# STM32WBA52xx register map
File version: 1.0
Registers are 32-bit, read-write, reset 0x0 unless marked. A register's access mark holds for its fields unless they carry their own. Offsets are from the block's base; [hi:lo] are bit positions; {n}, {i} and the like mark numbered series; 'fields as' and 'values as' point back to an identical list.

## GPDMA1 — DMA Controller
Base 0x40020000
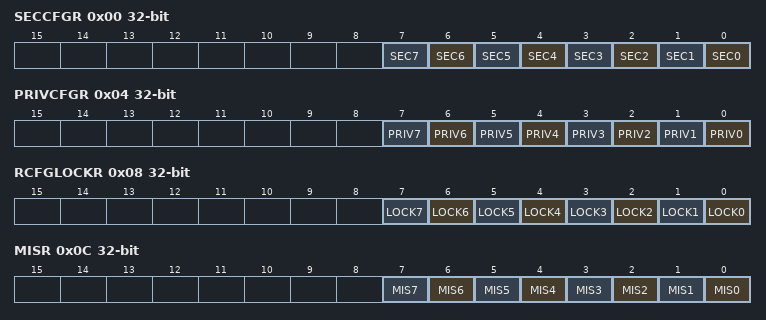
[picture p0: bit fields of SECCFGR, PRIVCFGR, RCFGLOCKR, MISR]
0x00 SECCFGR — DMA secure configuration register
  [n] SEC{n} (n=0..7) — Secure State of Channel {n}
0x04 PRIVCFGR — DMA privileged configuration register
  [n] PRIV{n} (n=0..7) — Privileged State of Channel {n}
0x08 RCFGLOCKR — DMA secure and privilege lock register
  [n] LOCK{n} (n=0..7) — Privileged and Secure State Lock of Channel {n}
0x0C MISR — DMA non secure masked interrupt status register
  [n] MIS{n} (n=0..7) — Masked Interrupt State of Non-Secure Channel {n}
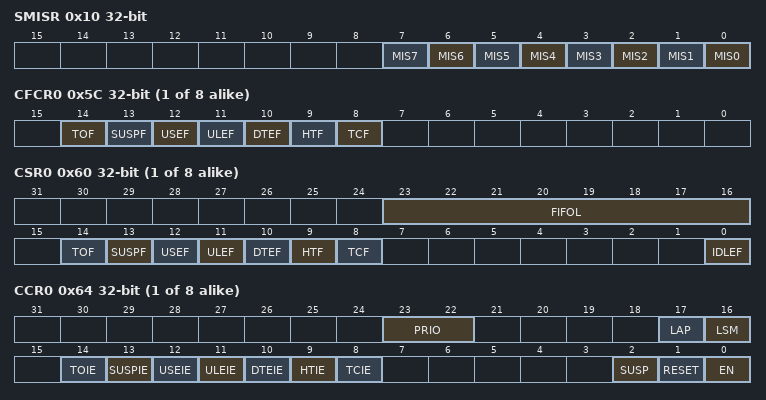
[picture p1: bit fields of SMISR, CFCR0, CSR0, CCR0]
0x10 SMISR — DMA secure masked interrupt status register
  [n] MIS{n} (n=0..7) — Masked Interrupt State of Secure Channel {n}
{0x50+0x80*i} CLBAR{i} (i=0..7) — DMA channel x linked-list base address register
  [31:16] LBA — Linked-list Base Address of DMA channel x
{0x5C+0x80*i} CFCR{i} (i=0..7) — DMA channel x flag clear register
  [14] TOF — Trigger overrun flag clear
  [13] SUSPF — Completed suspension flag clear
  [12] USEF — User setting error flag clear
  [11] ULEF — Update linked-list item error flag clear
  [10] DTEF — Data transfer error flag clear
  [9] HTF — Half transfer complete flag clear
  [8] TCF — Transfer complete flag clear
{0x60+0x80*i} CSR{i} (i=0..7) — DMA channel x flag status register
  [23:16] FIFOL — Monitored FIFO level in bytes
  [14] TOF — Trigger overrun event flag
  [13] SUSPF — User setting error flag
  [12] USEF — User setting error flag
  [11] ULEF — Update linked-list item error flag
  [10] DTEF — Data transfer error flag
  [9] HTF — Half transfer complete flag
  [8] TCF — Transfer complete flag
  [0] IDLEF — Idle flag
{0x64+0x80*i} CCR{i} (i=0..7) — DMA channel x control register
  [23:22] PRIO — Priority level
  [17] LAP — Linked-list allocated port
  [16] LSM — Link step mode
  [14] TOIE — Trigger overrun interrupt enable
  [13] SUSPIE — Completed suspension interrupt enable
  [12] USEIE — User setting error interrupt enable
  [11] ULEIE — Update linked-list item error interrupt enable
  [10] DTEIE — Data transfer error interrupt enable
  [9] HTIE — Half transfer complete interrupt enable
  [8] TCIE — Transfer complete interrupt enable
  [2] SUSP — Channel suspend
  [1] RESET — Channel reset
  [0] EN — Channel enable
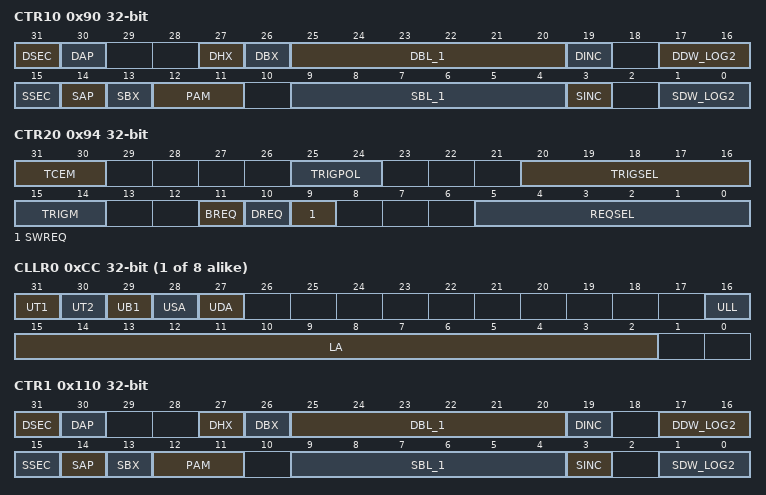
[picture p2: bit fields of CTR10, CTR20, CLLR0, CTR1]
0x90 CTR10 — DMA channel x transfer register 1
  [31] DSEC — Security attribute of the DMA transfer from the destination
  [30] DAP — Destination allocated port
  [27] DHX — Destination half-word exchange
  [26] DBX — Destination byte exchange
  [25:20] DBL_1 — Destination burst length minus 1
  [19] DINC — Destination incrementing burst
  [17:16] DDW_LOG2 — Binary logarithm of the destination data width of a burst
  [15] SSEC — Security attribute of the DMA transfer from the source
  [14] SAP — Source allocated port
  [13] SBX — Source byte exchange within the unaligned half-word of each source word
  [12:11] PAM — Padding / alignment mode
  [9:4] SBL_1 — Source burst length minus 1
  [3] SINC — Source incrementing burst
  [1:0] SDW_LOG2 — Binary logarithm of the source data width of a burst
0x94 CTR20 — DMA channel x transfer register 2
  [31:30] TCEM — Transfer complete event mode
  [25:24] TRIGPOL — Trigger event polarity
  [20:16] TRIGSEL — Trigger event input selection
  [15:14] TRIGM — Trigger mode
  [11] BREQ — Block hardware request
  [10] DREQ — Destination hardware request
  [9] SWREQ — Software request
  [5:0] REQSEL — DMA hardware request selection
0x98 CBR10 — DMA channel x block register 1
  [15:0] BNDT — Block number of data bytes to transfer from the source
{0x9C+0x80*i} CSAR{i} (i=0..7) — DMA channel x source address register
  [31:0] SA — Source Address
{0xA0+0x80*i} CDAR{i} (i=0..7) — DMA channel x destination address register
  [31:0] DA — Destination address
{0xCC+0x80*i} CLLR{i} (i=0..7) — DMA channel x linked-list address register
  [31] UT1 — Update transfer register 1 from SRAM
  [30] UT2 — Update transfer register 2 from SRAM
  [29] UB1 — Update block register 1 from SRAM
  [28] USA — Update source address register from SRAM
  [27] UDA — Update destination address register from SRAM
  [16] ULL — Update link address register from memory
  [15:2] LA — Pointer to the next linked-list data structure
0x110 CTR1 — DMA channel x transfer register 1
  fields as CTR10
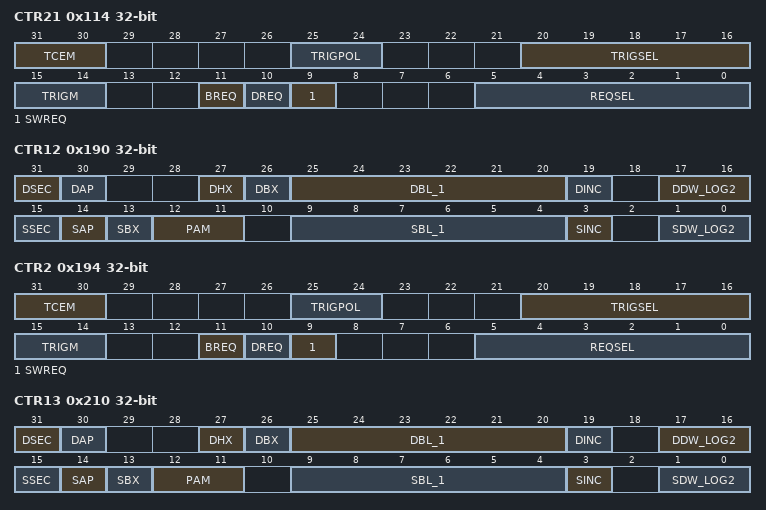
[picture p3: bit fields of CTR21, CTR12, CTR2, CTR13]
0x114 CTR21 — DMA channel x transfer register 2
  fields as CTR20
0x118 CBR1 — DMA channel x block register 1
  [15:0] BNDT — Block number of data bytes to transfer from the source
0x190 CTR12 — DMA channel x transfer register 1
  fields as CTR10
0x194 CTR2 — DMA channel x transfer register 2
  fields as CTR20
0x198 CBR12 — DMA channel x block register 1
  [15:0] BNDT — Block number of data bytes to transfer from the source
0x210 CTR13 — DMA channel x transfer register 1
  fields as CTR10
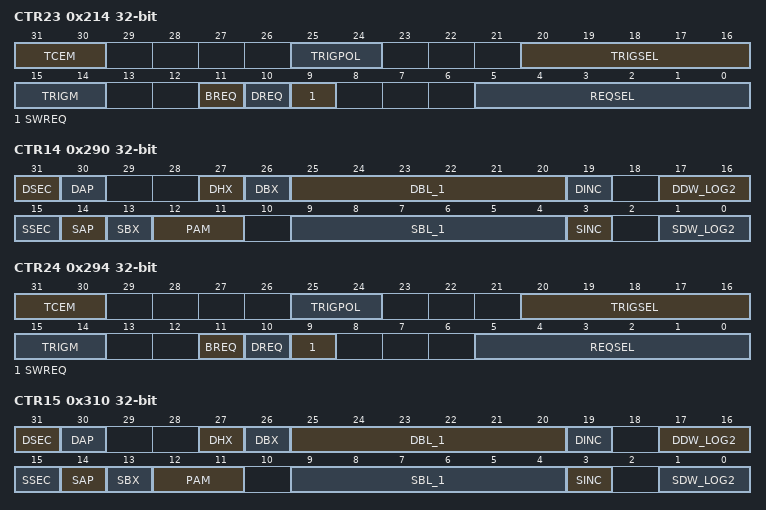
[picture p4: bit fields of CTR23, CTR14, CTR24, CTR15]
0x214 CTR23 — DMA channel x transfer register 2
  fields as CTR20
0x218 CBR13 — DMA channel x block register 1
  [15:0] BNDT — Block number of data bytes to transfer from the source
0x290 CTR14 — DMA channel x transfer register 1
  fields as CTR10
0x294 CTR24 — DMA channel x transfer register 2
  fields as CTR20
0x298 CBR14 — DMA channel x block register 1
  [15:0] BNDT — Block number of data bytes to transfer from the source
0x310 CTR15 — DMA channel x transfer register 1
  fields as CTR10
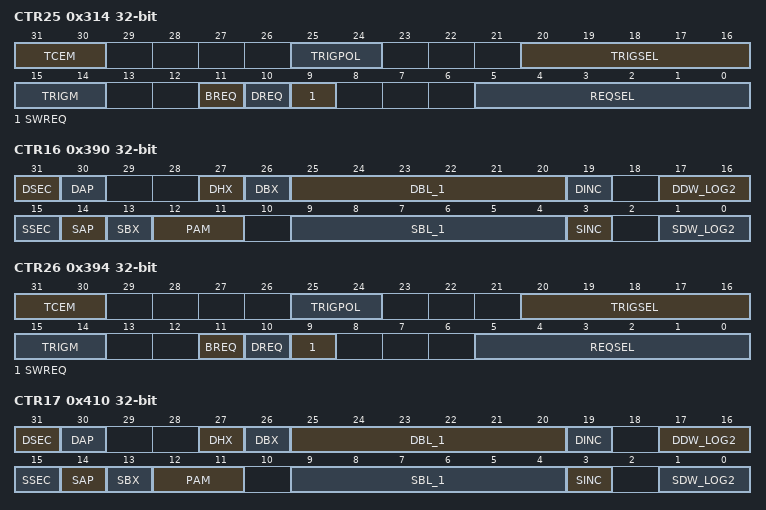
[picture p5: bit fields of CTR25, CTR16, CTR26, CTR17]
0x314 CTR25 — DMA channel x transfer register 2
  fields as CTR20
0x318 CBR15 — DMA channel x block register 1
  [15:0] BNDT — Block number of data bytes to transfer from the source
0x390 CTR16 — DMA channel x transfer register 1
  fields as CTR10
0x394 CTR26 — DMA channel x transfer register 2
  fields as CTR20
0x398 CBR16 — DMA channel x block register 1
  [15:0] BNDT — Block number of data bytes to transfer from the source
0x410 CTR17 — DMA channel x transfer register 1
  fields as CTR10
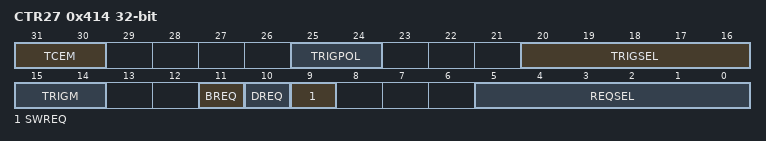
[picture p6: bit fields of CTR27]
0x414 CTR27 — DMA channel x transfer register 2
  fields as CTR20
0x418 CBR17 — DMA channel x block register 1
  [15:0] BNDT — Block number of data bytes to transfer from the source
